# YTM32B1HA0 register map
Vendor: YTMicro; File version: 1.0
CPU: little endian, MPU, FPU, 2 interrupt priority bits
Registers are 32-bit, read-write, reset 0x0 unless marked. A register's access mark holds for its fields unless they carry their own. Offsets are from the block's base; [hi:lo] are bit positions; {n}, {i} and the like mark numbered series; 'fields as' and 'values as' point back to an identical list.

## ENET (part 4 of 10) — Ethernet Quality-of-Service
Base 0x401E4000; register names take the prefix ENET_
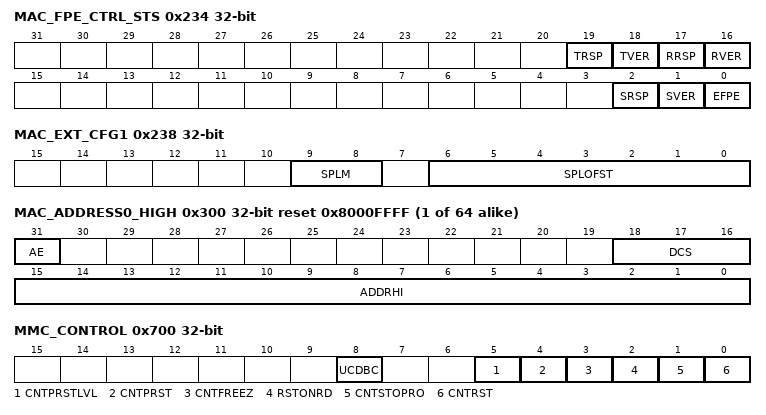
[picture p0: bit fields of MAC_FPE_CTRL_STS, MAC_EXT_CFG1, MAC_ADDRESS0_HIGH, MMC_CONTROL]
0x234 MAC_FPE_CTRL_STS — This register controls the operation of Frame Preemption.
  [19] TRSP — Set when a Respond mPacket is transmitted (triggered by setting SRSP field). An interrupt can be generated for this event if FPEIE bit of MAC_Interrupt_Enable is set. Access restriction applies. Clears on read (or write of 1 when RCWE bit in MAC_CSR_SW_Ctrl register is set). Self-set to 1 on internal event.
    0=Not transmitted Respond Frame; 1=Transmitted Respond Frame
  [18] TVER — Set when a Verify mPacket is transmitted (triggered by setting SVER field). An interrupt can be generated for this event if FPEIE bit of MAC_Interrupt_Enable is set. Access restriction applies. Clears on read (or write of 1 when RCWE bit in MAC_CSR_SW_Ctrl register is set). Self-set to 1 on internal event.
    0=Not transmitted Verify Frame; 1=Transmitted Verify Frame
  [17] RRSP — Set when a Respond mPacket is received (triggered by setting SRSP field). An interrupt can be generated for this event if FPEIE bit of MAC_Interrupt_Enable is set. Access restriction applies. Clears on read (or write of 1 when RCWE bit in MAC_CSR_SW_Ctrl register is set). Self-set to 1 on internal event.
    0=Not received Respond Frame; 1=Received Respond Frame
  [16] RVER — Set when a Verify mPacket is received (triggered by setting SVER field). An interrupt can be generated for this event if FPEIE bit of MAC_Interrupt_Enable is set. Access restriction applies. Clears on read (or write of 1 when RCWE bit in MAC_CSR_SW_Ctrl register is set). Self-set to 1 on internal event.
    0=Not received Verify Frame; 1=Received Verify Frame
  [2] SRSP — When set indicates hardware to send a Respond mPacket. Reset by hardware after sending the Respond mPacket. Access restriction applies. Setting 1 sets. Self-cleared. Setting 0 has no effect.
    0=Send Respond mPacket is disabled; 1=Send Respond mPacket is enabled
  [1] SVER — When set indicates hardware to send a Verify mPacket. Reset by hardware after sending the Verify mPacket. Access restriction applies. Setting 1 sets. Self-cleared. Setting 0 has no effect.
    0=Send Verify mPacket is disabled; 1=Send Verify mPacket is enabled
  [0] EFPE — When set Frame Preemption Tx functionality is enabled.
    0=Tx Frame Preemption is disabled; 1=Tx Frame Preemption is enabled
0x238 MAC_EXT_CFG1 — This register contains Split mode control field and offset field for Split Header feature.
  [9:8] SPLM — These bits indicate the mode of splitting the incoming Rx packets. They are
    0=Split at L3/L4 header; 1=Split at L2 header with an offset. Always Split at SPLOFST bytes from the beginning of Length/Type field of the Frame; 2=Combination mode: Split similar to SPLM=00 for IP packets that are untagged or tagged and VLAN stripped
  [6:0] SPLOFST — These bits indicate the value of offset from the beginning of Length/Type field at which header split should take place when the appropriate SPLM is selected. The reset value of this field is 2 bytes indicating a split at L2 header. Value is in terms of bytes.
0x240 MAC_PRESN_TIME_NS — This register contains the 32-bit binary rollover equivalent time of the PTP System Time in ns
  [31:0] MPTN — These bits indicate the value of the 32-bit binary rollover equivalent time of the PTP System Time in ns
0x244 MAC_PRESN_TIME_UPDT — This field holds the 32-bit value of MAC 1722 Presentation Time in ns, that should be added to the Current Presentation Time Counter value. Init happens when TSINIT is set, and update happens when the TSUPDT bit is set (TSINIT and TSINIT defined in MAC_Timestamp_ Control register).
  [31:0] MPTU — This field holds the init value or the update value for the presentation time. When used for update, this field holds the 32-bit value in ns, that should be added to the Current Presentation Time Counter value. Init happens when TSINIT is set, and update happens when the TSUPDT bit is set (TSINIT and TSINIT defined in MAC_Timestamp_ Control register). When ADDSUB field of MAC_System_Time_Nanoseconds_Update is set, this value is directly used for subtraction
{0x300+8i} MAC_ADDRESS{i}_HIGH reset 0x8000FFFF (i=0..63) — The MAC Address0 High register holds the upper 16 bits of the first 6-byte MAC address of the station. The first DA byte that is received on the (G)MII interface corresponds to the LS byte (Bits [7:0]) of the MAC Address Low register. For example, if 0x112233445566 is received (0x11 in lane 0 of the first column) on the (G)MII as the destination address, then the MacAddress0 Register [47:0] is compared with 0x665544332211. If the MAC address registers are configured to be double-synchronized to the (G)MII clock domains, then the synchronization is triggered only when Bits[31:24] (in little-endian mode) or Bits[7:0] (in big-endian mode) of the MAC Address0 Low Register are written. For proper synchronization updates, the consecutive writes to this Address Low Register should be performed after at least four clock cycles in the destination clock domain.
  [31] AE ro — This bit is always set to 1.
    0=INVALID : This bit must be always set to 1; 1=This bit is always set to 1
  [18:16] DCS — If the PDC bit of MAC_Ext_Configuration register is not set: This field contains the binary representation of the DMA Channel number to which an Rx packet whose DA matches the MAC Address0 content is routed. If the PDC bit of MAC_Ext_Configuration register is set: This field contains the one-hot representation of one or more DMA Channel numbers to which an Rx packet whose DA matches the MAC Address0 content is routed.
  [15:0] ADDRHI — This field contains the upper 16 bits [47:32] of the first 6-byte MAC address. The MAC uses this field for filtering the received packets and inserting the MAC address in the Transmit Flow Control (Pause) Packets.
{0x304+8i} MAC_ADDRESS{i}_LOW reset 0xFFFFFFFF (i=0..63)
  [31:0] ADDRLO — This field contains the lower 32 bits [31:0] of the first 6-byte MAC address. The MAC uses this field for filtering the received packets and inserting the MAC address in the Transmit Flow Control (Pause) Packets.
0x700 MMC_CONTROL — This register establishes the operating mode of MMC.
  [8] UCDBC — Note: The CNTRST bit has a higher priority than the CNTPRST bit. Therefore, when the software tries to set both bits in the same write cycle, all counters are cleared and the CNTPRST bit is not set. When set, the MAC updates all related MMC Counters for Broadcast packets that are dropped because of the setting of the DBF bit of MAC_Packet_Filter register. When reset, the MMC Counters are not updated for dropped Broadcast packets.
    0=Update MMC Counters for Dropped Broadcast Packets is disabled; 1=Update MMC Counters for Dropped Broadcast Packets is enabled
  [5] CNTPRSTLVL — When this bit is low and the CNTPRST bit is set, all MMC counters get preset to almost-half value. All octet counters get preset to 0x7FFF_F800 (Half 2KBytes) and all packet-counters gets preset to 0x7FFF_FFF0 (Half 16). When this bit is high and the CNTPRST bit is set, all MMC counters get preset to almost-full value. All octet counters get preset to 0xFFFF_F800 (Full 2KBytes) and all packet-counters gets preset to 0xFFFF_FFF0 (Full 16). For 16-bit counters, the almost-half preset values are 0x7800 and 0x7FF0 for the respective octet and packet counters. Similarly, the almost-full preset values for the 16-bit counters are 0xF800 and 0xFFF0.
    0=Full-Half Preset is disabled; 1=Full-Half Preset is enabled
  [4] CNTPRST — When this bit is set, all counters are initialized or preset to almost full or almost half according to the CNTPRSTLVL bit. This bit is cleared automatically after 1 clock cycle. This bit, along with the CNTPRSTLVL bit, is useful for debugging and testing the assertion of interrupts because of MMC counter becoming half-full or full. Access restriction applies. Self-cleared. Setting 0 clears. Setting 1 sets.
    0=Counters Preset is disabled; 1=Counters Preset is enabled
  [3] CNTFREEZ — When this bit is set, it freezes all MMC counters to their current value. Until this bit is reset to 0, no MMC counter is updated because of any transmitted or received packet. If any MMC counter is read with the Reset on Read bit set, then that counter is also cleared in this mode.
    0=MMC Counter Freeze is disabled; 1=MMC Counter Freeze is enabled
  [2] RSTONRD — When this bit is set, the MMC counters are reset to zero after Read (self-clearing after reset). The counters are cleared when the least significant byte lane (Bits[7:0]) is read.
    0=Reset on Read is disabled; 1=Reset on Read is enabled
  [1] CNTSTOPRO — When this bit is set, the counter does not roll over to zero after reaching the maximum value.
    0=Counter Stop Rollover is disabled; 1=Counter Stop Rollover is enabled
  [0] CNTRST — When this bit is set, all counters are reset. This bit is cleared automatically after 1 clock cycle. Access restriction applies. Self-cleared. Setting 0 clears. Setting 1 sets.
    0=Counters are not reset; 1=All counters are reset
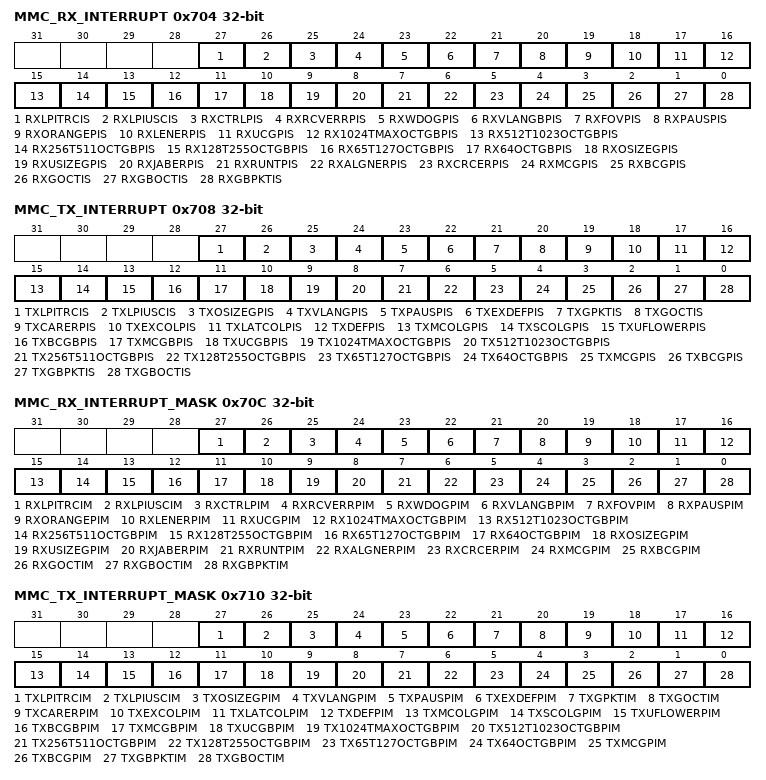
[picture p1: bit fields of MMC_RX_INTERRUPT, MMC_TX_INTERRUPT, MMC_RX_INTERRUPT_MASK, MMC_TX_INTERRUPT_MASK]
0x704 MMC_RX_INTERRUPT ro — This register maintains the interrupts generated from all Receive statistics counters. The MMC Receive Interrupt register maintains the interrupts that are generated when the following occur: - Receive statistic counters reach half of their maximum values (0x8000_0000 for 32 bit counter and 0x8000 for 16 bit counter). - Receive statistic counters cross their maximum values (0xFFFF_FFFF for 32 bit counter and 0xFFFF for 16 bit counter). When the Counter Stop Rollover is set, interrupts are set but the counter remains at all-ones. The MMC Receive Interrupt register is a 32 bit register. An interrupt bit is cleared when the respective MMC counter that caused the interrupt is read. The least significant byte lane (Bits[7:0]) of the respective counter must be read to clear the interrupt bit. Note: R_SS_RC means that this register bit is set internally, and it is cleared when the Counter register is read.
  [27] RXLPITRCIS rw — This bit is set when the Rx_LPI_Tran_Cntr counter reaches half of the maximum value or the maximum value. Access restriction applies. Clears on read. Self-set to 1 on internal event.
    0=MMC Receive LPI transition Counter Interrupt Status not detected; 1=MMC Receive LPI transition Counter Inter- rupt Status detected
  [26] RXLPIUSCIS rw — This bit is set when the Rx_LPI_USEC_Cntr counter reaches half of the maximum value or the maximum value. Access restriction applies. Clears on read. Self-set to 1 on internal event.
    0=MMC Receive LPI microsecond Counter Interrupt Status not detected; 1=MMC Receive LPI microsecond Counter Interrupt Status detected
  [25] RXCTRLPIS rw — This bit is set when the rxctrlpackets_g counter reaches half of the maximum value or the maximum value. Access restriction applies. Clears on read. Self-set to 1 on internal event.
    0=MMC Receive Control Packet Counter Interrupt Status not detected; 1=MMC Receive Control Packet Counter Interrupt Status detected
  [24] RXRCVERRPIS rw — This bit is set when the rxrcverror counter reaches half of the maximum value or the maximum value. Access restriction applies. Clears on read. Self-set to 1 on internal event.
    0=MMC Receive Error Packet Counter Interrupt Status not detected; 1=MMC Receive Error Packet Counter Inter- rupt Status detected
  [23] RXWDOGPIS rw — This bit is set when the rxwatchdog error counter reaches half of the maximum value or the maximum value. Access restriction applies. Clears on read. Self-set to 1 on internal event.
    0=MMC Receive Watchdog Error Packet Counter Interrupt Status not detected; 1=MMC Receive Watchdog Error Packet Counter Interrupt Status detected
  [22] RXVLANGBPIS rw — This bit is set when the rxvlanpackets_gb counter reaches half of the maximum value or the maximum value. Access restriction applies. Clears on read. Self-set to 1 on internal event.
    0=MMC Receive VLAN Good Bad Packet Counter Interrupt Status not detected; 1=MMC Receive VLAN Good Bad Packet Counter Interrupt Status detected
  [21] RXFOVPIS rw — This bit is set when the rxfifoflow counter reaches half of the maximum value or the maximum value. Access restriction applies. Clears on read. Self-set to 1 on internal event.
    0=MMC Receive FIFO Overflow Packet Counter Interrupt Status not detected; 1=MMC Receive FIFO Overflow Packet Counter Interrupt Status detected
  [20] RXPAUSPIS rw — This bit is set when the rxpausepackets counter reaches half of the maximum value or the maximum value. Access restriction applies. Clears on read. Self-set to 1 on internal event.
    0=MMC Receive Pause Packet Counter Interrupt Status not detected; 1=MMC Receive Pause Packet Counter Interrupt Status detected
  [19] RXORANGEPIS rw — This bit is set when the rxoutofrangetype counter reaches half of the maximum value or the maximum value. Access restriction applies. Clears on read. Self-set to 1 on internal event.
    0=MMC Receive Out Of Range Error Packet Counter Interrupt Status not detected; 1=MMC Receive Out Of Range Error Packet Counter Interrupt Status detected
  [18] RXLENERPIS rw — This bit is set when the rxlengtherror counter reaches half of the maximum value or the maximum value. Access restriction applies. Clears on read. Self-set to 1 on internal event.
    0=MMC Receive Length Error Packet Counter Interrupt Status not detected; 1=MMC Receive Length Error Packet Counter Interrupt Status detected
  [17] RXUCGPIS rw — This bit is set when the rxunicastpackets_g counter reaches half of the maximum value or the maximum value. Access restriction applies. Clears on read. Self-set to 1 on internal event.
    0=MMC Receive Unicast Good Packet Counter Interrupt Status not detected; 1=MMC Receive Unicast Good Packet Counter Interrupt Status detected
  [16] RX1024TMAXOCTGBPIS rw — This bit is set when the rx1024tomaxoctets_gb counter reaches half of the maximum value or the maximum value. Access restriction applies. Clears on read. Self-set to 1 on internal event.
    0=MMC Receive 1024 to Maximum Octets Good Bad Packet Counter Interrupt Status not detected; 1=MMC Receive 1024 to Maximum Octets Good Bad Packet Counter Interrupt Status detected
  [15] RX512T1023OCTGBPIS rw — This bit is set when the rx512to1023octets_gb counter reaches half of the maximum value or the maximum value. Access restriction applies. Clears on read. Self-set to 1 on internal event.
    0=MMC Receive 512 to 1023 Octets Good Bad Packet Counter Interrupt Status not detected; 1=MMC Receive 512 to 1023 Octets Good Bad Packet Counter Interrupt Status detected
  [14] RX256T511OCTGBPIS rw — This bit is set when the rx256to511octets_gb counter reaches half of the maximum value or the maximum value. Access restriction applies. Clears on read. Self-set to 1 on internal event.
    0=MMC Receive 256 to 511 Octets Good Bad Packet Counter Interrupt Status not detected; 1=MMC Receive 256 to 511 Octets Good Bad Packet Counter Interrupt Status detected
  [13] RX128T255OCTGBPIS rw — This bit is set when the rx128to255octets_gb counter reaches half of the maximum value or the maximum value. Access restriction applies. Clears on read. Self-set to 1 on internal event.
    0=MMC Receive 128 to 255 Octets Good Bad Packet Counter Interrupt Status not detected; 1=MMC Receive 128 to 255 Octets Good Bad Packet Counter Interrupt Status detected
  [12] RX65T127OCTGBPIS rw — This bit is set when the rx65to127octets_gb counter reaches half of the maximum value or the maximum value. Access restriction applies. Clears on read. Self-set to 1 on internal event.
    0=MMC Receive 65 to 127 Octets Good Bad Packet Counter Interrupt Status not detected; 1=MMC Receive 65 to 127 Octets Good Bad Packet Counter Interrupt Status detected
  [11] RX64OCTGBPIS rw — This bit is set when the rx64octets_gb counter reaches half of the maximum value or the maximum value. Access restriction applies. Clears on read. Self-set to 1 on internal event.
    0=MMC Receive 64 Octets Good Bad Packet Counter Interrupt Status not detected; 1=MMC Receive 64 Octets Good Bad Packet Counter Interrupt Status detected
  [10] RXOSIZEGPIS rw — This bit is set when the rxoversize_g counter reaches half of the maximum value or the maximum value. Access restriction applies. Clears on read. Self-set to 1 on internal event.
    0=MMC Receive Oversize Good Packet Counter Interrupt Status not detected; 1=MMC Receive Oversize Good Packet Counter Interrupt Status detected
  [9] RXUSIZEGPIS rw — This bit is set when the rxundersize_g counter reaches half of the maximum value or the maximum value. Access restriction applies. Clears on read. Self-set to 1 on internal event.
    0=MMC Receive Undersize Good Packet Counter Interrupt Status not detected; 1=MMC Receive Undersize Good Packet Counter Interrupt Status detected
  [8] RXJABERPIS rw — This bit is set when the rxjabber counter reaches half of the maximum value or the maximum value. Access restriction applies. Clears on read. Self-set to 1 on internal event.
    0=MMC Receive Jabber Error Packet Counter Interrupt Status not detected; 1=MMC Receive Jabber Error Packet Counter Interrupt Status detected
  [7] RXRUNTPIS rw — This bit is set when the rxrunt counter reaches half of the maximum value or the maximum value. Access restriction applies. Clears on read. Self-set to 1 on internal event.
    0=MMC Receive Runt Packet Counter Interrupt Status not detected; 1=MMC Receive Runt Packet Counter Interrupt Status detected
  [6] RXALGNERPIS rw — This bit is set when the rxalignmenterror counter reaches half of the maximum value or the maximum value. Access restriction applies. Clears on read. Self-set to 1 on internal event.
    0=MMC Receive Alignment Error Packet Counter Interrupt Status not detected; 1=MMC Receive Alignment Error Packet Counter Interrupt Status detected
  [5] RXCRCERPIS rw — This bit is set when the rxcrcerror counter reaches half of the maximum value or the maximum value. Access restriction applies. Clears on read. Self-set to 1 on internal event.
    0=MMC Receive CRC Error Packet Counter Interrupt Status not detected; 1=MMC Receive CRC Error Packet Counter Interrupt Status detected
  [4] RXMCGPIS rw — This bit is set when the rxmulticast_g counter reaches half of the maximum value or the maximum value. Access restriction applies. Clears on read. Self-set to 1 on internal event.
    0=MMC Receive Multicast Good Packet Counter Interrupt Status not detected; 1=MMC Receive Multicast Good Packet Counter Interrupt Status detected
  [3] RXBCGPIS rw — This bit is set when the rxbroadcast_g counter reaches half of the maximum value or the maximum value. Access restriction applies. Clears on read. Self-set to 1 on internal event.
    0=MMC Receive Broadcast Good Packet Counter Interrupt Status not detected; 1=MMC Receive Broadcast Good Packet Counter Interrupt Status detected
  [2] RXGOCTIS rw — This bit is set when the rxgoodoctets counter reaches half of the maximum value or the maximum value. Access restriction applies. Clears on read. Self-set to 1 on internal event.
    0=MMC Receive Good Octets Counter Interrupt Status not detected; 1=MMC Receive Good Octets Counter Interrupt Status detected
  [1] RXGBOCTIS rw — This bit is set when the rxgoodandbadoctets counter reaches half of the maximum value or the maximum value. Access restriction applies. Clears on read. Self-set to 1 on internal event.
    0=MMC Receive Good and Bad Octets Counter Interrupt Status not detected; 1=MMC Receive Good and Bad Octets Counter Interrupt Status detected
  [0] RXGBPKTIS rw — This bit is set when the rxgoodandbadpacket counter reaches half of the maximum value or the maximum value. Access restriction applies. Clears on read. Self-set to 1 on internal event.
    0=MMC Receive Good and Bad Packet Counter Interrupt Status not detected; 1=MMC Receive Good and Bad Packet Counter Interrupt Status detected
0x708 MMC_TX_INTERRUPT ro — This register contains the interrupt status bits for the MMC Transmit counters.
  [27] TXLPITRCIS rw — This bit is set when the Tx_LPI_Tran_Cntr counter reaches half of the maximum value or the maximum value. Access restriction applies. Clears on read. Self-set to 1 on internal event.
    0=MMC Transmit LPI transition counter interrupt status not detected; 1=MMC Transmit LPI transition counter interrupt status detected
  [26] TXLPIUSCIS rw — This bit is set when the Tx_LPI_USEC_Cntr counter reaches half of the maximum value or the maximum value. Access restriction applies. Clears on read. Self-set to 1 on internal event.
    0=MMC Transmit LPI microsecond counter interrupt status not detected; 1=MMC Transmit LPI microsecond counter interrupt status detected
  [25] TXOSIZEGPIS rw — This bit is set when the txoversize_g counter reaches half of the maximum value or the maximum value. Access restriction applies. Clears on read. Self-set to 1 on internal event.
    0=MMC Transmit Oversize Good Packet Counter Interrupt Status not detected; 1=MMC Transmit Oversize Good Packet Counter Interrupt Status detected
  [24] TXVLANGPIS rw — MMC Transmit VLAN Good Packet Counter Interrupt Status This bit is set when the txvlanpackets_g counter reaches half of the maximum value or the maximum value. Access restriction applies. Clears on read. Self-set to 1 on internal event.
    0=MMC Transmit VLAN Good Packet Counter Interrupt Status not detected; 1=MMC Transmit VLAN Good Packet Counter Interrupt Status detected
  [23] TXPAUSPIS rw — This bit is set when the txpausepacketserror counter reaches half of the maximum value or the maximum value. Access restriction applies. Clears on read. Self-set to 1 on internal event.
    0=MMC Transmit Pause Packet Counter Interrupt Status not detected; 1=MMC Transmit Pause Packet Counter Interrupt Status detected
  [22] TXEXDEFPIS rw — This bit is set when the txexcessdef counter reaches half of the maximum value or the maximum value. Access restriction applies. Clears on read. Self-set to 1 on internal event.
    0=MMC Transmit Excessive Deferral Packet Counter Interrupt Status not detected; 1=MMC Transmit Excessive Deferral Packet Counter Interrupt Status detected
  [21] TXGPKTIS rw — This bit is set when the txpacketcount_g counter reaches half of the maximum value or the maximum value. Access restriction applies. Clears on read. Self-set to 1 on internal event.
    0=MMC Transmit Good Packet Counter Interrupt Status not detected; 1=MMC Transmit Good Packet Counter Interrupt Status detected
  [20] TXGOCTIS rw — This bit is set when the txoctetcount_g counter reaches half of the maximum value or the maximum value. Access restriction applies. Clears on read. Self-set to 1 on internal event.
    0=MMC Transmit Good Octets Counter Interrupt Status not detected; 1=MMC Transmit Good Octets Counter Interrupt Status detected
  [19] TXCARERPIS rw — This bit is set when the txcarriererror counter reaches half of the maximum value or the maximum value. Access restriction applies. Clears on read. Self-set to 1 on internal event.
    0=MMC Transmit Carrier Error Packet Counter Interrupt Status not detected; 1=MMC Transmit Carrier Error Packet Counter Interrupt Status detected
  [18] TXEXCOLPIS rw — This bit is set when the txexesscol counter reaches half of the maximum value or the maximum value. Access restriction applies. Clears on read. Self-set to 1 on internal event.
    0=MMC Transmit Excessive Collision Packet Counter Interrupt Status not detected; 1=MMC Transmit Excessive Collision Packet Counter Interrupt Status detected
  [17] TXLATCOLPIS rw — This bit is set when the txlatecol counter reaches half of the maximum value or the maximum value. Access restriction applies. Clears on read. Self-set to 1 on internal event.
    0=MMC Transmit Late Collision Packet Counter Interrupt Status not detected; 1=MMC Transmit Late Collision Packet Counter Interrupt Status detected
  [16] TXDEFPIS rw — This bit is set when the txdeferred counter reaches half of the maximum value or the maximum value. Access restriction applies. Clears on read. Self-set to 1 on internal event.
    0=MMC Transmit Deferred Packet Counter Interrupt Status not detected; 1=MMC Transmit Deferred Packet Counter Interrupt Status detected
  [15] TXMCOLGPIS rw — This bit is set when the txmulticol_g counter reaches half of the maximum value or the maximum value. Access restriction applies. Clears on read. Self-set to 1 on internal event.
    0=MMC Transmit Multiple Collision Good Packet Counter Interrupt Status not detected; 1=MMC Transmit Multiple Collision Good Packet Counter Interrupt Status detected
  [14] TXSCOLGPIS rw — This bit is set when the txsinglecol_g counter reaches half of the maximum value or the maximum value. Access restriction applies. Clears on read. Self-set to 1 on internal event.
    0=MMC Transmit Single Collision Good Packet Counter Interrupt Status not detected; 1=MMC Transmit Single Collision Good Packet Counter Interrupt Status detected
  [13] TXUFLOWERPIS rw — This bit is set when the txunderflowerror counter reaches half of the maximum value or the maximum value. Access restriction applies. Clears on read. Self-set to 1 on internal event.
    0=MMC Transmit Underflow Error Packet Counter Interrupt Status not detected; 1=MMC Transmit Underflow Error Packet Counter Interrupt Status detected
  [12] TXBCGBPIS rw — This bit is set when the txbroadcastpackets_gb counter reaches half of the maximum value or the maximum value. Access restriction applies. Clears on read. Self-set to 1 on internal event.
    0=MMC Transmit Broadcast Good Packet Counter Interrupt Status not detected; 1=MMC Transmit Broadcast Good Packet Counter Interrupt Status detected
  [11] TXMCGBPIS rw — This bit is set when the txmulticastpackets_gb counter reaches half of the maximum value or the maximum value. Access restriction applies. Clears on read. Self-set to 1 on internal event.
    0=MMC Transmit Multicast Good Packet Counter Interrupt Status not detected; 1=MMC Transmit Multicast Good Packet Counter Interrupt Status detected
  [10] TXUCGBPIS rw — This bit is set when the txunicastpackets_gb counter reaches half of the maximum value or the maximum value. Access restriction applies. Clears on read. Self-set to 1 on internal event.
    0=MMC Transmit Unicast Good Bad Packet Counter Interrupt Status not detected; 1=MMC Transmit Unicast Good Bad Packet Counter Interrupt Status detected
  [9] TX1024TMAXOCTGBPIS rw — This bit is set when the tx1024tomaxoctets_gb counter reaches half of the maximum value or the maximum value. Access restriction applies. Clears on read. Self-set to 1 on internal event.
    0=MMC Transmit 1024 to Maximum Octet Good Bad Packet Counter Interrupt Status not detected; 1=MMC Transmit 1024 to Maximum Octet Good Bad Packet Counter Interrupt Status detected
  [8] TX512T1023OCTGBPIS rw — This bit is set when the tx512to1023octets_gb counter reaches half of the maximum value or the maximum value. Access restriction applies. Clears on read. Self-set to 1 on internal event.
    0=MMC Transmit 512 to 1023 Octet Good Bad Packet Counter Interrupt Status not detected; 1=MMC Transmit 512 to 1023 Octet Good Bad Packet Counter Interrupt Status detected
  [7] TX256T511OCTGBPIS rw — This bit is set when the tx256to511octets_gb counter reaches half of the maximum value or the maximum value. Access restriction applies. Clears on read. Self-set to 1 on internal event.
    0=MMC Transmit 256 to 511 Octet Good Bad Packet Counter Interrupt Status not detected; 1=MMC Transmit 256 to 511 Octet Good Bad Packet Counter Interrupt Status detected
  [6] TX128T255OCTGBPIS rw — This bit is set when the tx128to255octets_gb counter reaches half of the maximum value or the maximum value. Access restriction applies. Clears on read. Self-set to 1 on internal event.
    0=MMC Transmit 128 to 255 Octet Good Bad Packet Counter Interrupt Status not detected; 1=MMC Transmit 128 to 255 Octet Good Bad Packet Counter Interrupt Status detected
  [5] TX65T127OCTGBPIS rw — This bit is set when the tx65to127octets_gb counter reaches half of the maximum value or the maximum value. Access restriction applies. Clears on read. Self-set to 1 on internal event.
    0=MMC Transmit 65 to 127 Octet Good Bad Packet Counter Interrupt Status not detected; 1=MMC Transmit 65 to 127 Octet Good Bad Packet Counter Interrupt Status detected
  [4] TX64OCTGBPIS rw — This bit is set when the tx64octets_gb counter reaches half of the maximum value or the maximum value. Access restriction applies. Clears on read. Self-set to 1 on internal event.
    0=MMC Transmit 64 Octet Good Bad Packet Counter Interrupt Status not detected; 1=MMC Transmit 64 Octet Good Bad Packet Counter Interrupt Status detected
  [3] TXMCGPIS rw — This bit is set when the txbroadcastpackets_g counter reaches half of the maximum value or the maximum value. Access restriction applies. Clears on read. Self-set to 1 on internal event.
    values as TXMCGBPIS
  [2] TXBCGPIS rw — This bit is set when the txmulticastpackets_g counter reaches half of the maximum value or the maximum value. Access restriction applies. Clears on read. Self-set to 1 on internal event.
    values as TXBCGBPIS
  [1] TXGBPKTIS rw — This bit is set when the txgoodbadpackets counter reaches half of the maximum value or the maximum value. Access restriction applies. Clears on read. Self-set to 1 on internal event.
    0=MMC Transmit Good Bad Packet Counter Interrupt Status not detected; 1=MMC Transmit Good Bad Packet Counter Interrupt Status detected
  [0] TXGBOCTIS rw — This bit is set when the txoctetcount_gb counter reaches half of the maximum value or the maximum value. Access restriction applies. Clears on read. Self-set to 1 on internal event.
    0=MMC Transmit Good Bad Octet Counter Interrupt Status not detected; 1=MMC Transmit Good Bad Octet Counter Interrupt Status detected
0x70C MMC_RX_INTERRUPT_MASK ro — This register maintains the masks for interrupts generated from all Receive statistics counters. The MMC Receive Interrupt Mask register maintains the masks for the interrupts generated when receive statistic counters reach half of their maximum value or the maximum values.
  [27] RXLPITRCIM rw — Setting this bit masks the interrupt when the Rx_LPI_Tran_Cntr counter reaches half of the maximum value or the maximum value.
    0=MMC Receive LPI transition counter inter- rupt Mask is disabled; 1=MMC Receive LPI transition counter inter- rupt Mask is enabled
  [26] RXLPIUSCIM rw — Setting this bit masks the interrupt when the Rx_LPI_USEC_Cntr counter reaches half of the maximum value or the maximum value.
    0=MMC Receive LPI microsecond counter interrupt Mask is disabled; 1=MMC Receive LPI microsecond counter interrupt Mask is enabled
  [25] RXCTRLPIM rw — Setting this bit masks the interrupt when the rxctrlpackets_g counter reaches half of the maximum value or the maximum value.
    0=MMC Receive Control Packet Counter Interrupt Mask is disabled; 1=MMC Receive Control Packet Counter Interrupt Mask is enabled
  [24] RXRCVERRPIM rw — Setting this bit masks the interrupt when the rxrcverror counter reaches half of the maximum value or the maximum value.
    0=MMC Receive Error Packet Counter Interrupt Mask is disabled; 1=MMC Receive Error Packet Counter Interrupt Mask is enabled
  [23] RXWDOGPIM rw — Setting this bit masks the interrupt when the rxwatchdogerror counter reaches half of the maximum value or the maximum value.
    0=MMC Receive Watchdog Error Packet Counter Interrupt Mask is disabled; 1=MMC Receive Watchdog Error Packet Counter Interrupt Mask is enabled
  [22] RXVLANGBPIM rw — Setting this bit masks the interrupt when the rxvlanpackets_gb counter reaches half of the maximum value or the maximum value.
    0=MMC Receive VLAN Good Bad Packet Counter Interrupt Mask is disabled; 1=MMC Receive VLAN Good Bad Packet Counter Interrupt Mask is enabled
  [21] RXFOVPIM rw — Setting this bit masks the interrupt when the rxfifooverflow counter reaches half of the maximum value or the maximum value.
    0=MMC Receive FIFO Overflow Packet Counter Interrupt Mask is disabled; 1=MMC Receive FIFO Overflow Packet Counter Interrupt Mask is enabled
  [20] RXPAUSPIM rw — Setting this bit masks the interrupt when the rxpausepackets counter reaches half of the maximum value or the maximum value.
    0=MMC Receive Pause Packet Counter Interrupt Mask is disabled; 1=MMC Receive Pause Packet Counter Interrupt Mask is enabled
  [19] RXORANGEPIM rw — Setting this bit masks the interrupt when the rxoutofrangetype counter reaches half of the maximum value or the maximum value.
    0=MMC Receive Out Of Range Error Packet Counter Interrupt Mask is disabled; 1=MMC Receive Out Of Range Error Packet Counter Interrupt Mask is enabled
  [18] RXLENERPIM rw — MMC Receive Length Error Packet Counter Interrupt Mask Setting this bit masks the interrupt when the rxlengtherror counter reaches half of the maximum value or the maximum value.
    0=MMC Receive Length Error Packet Counter Interrupt Mask is disabled; 1=MMC Receive Length Error Packet Counter Interrupt Mask is enabled
  [17] RXUCGPIM rw — Setting this bit masks the interrupt when the rxunicastpackets_g counter reaches half of the maximum value or the maximum value.
    0=MMC Receive Unicast Good Packet Counter Interrupt Mask is disabled; 1=MMC Receive Unicast Good Packet Counter Interrupt Mask is enabled
  [16] RX1024TMAXOCTGBPIM rw — Setting this bit masks the interrupt when the rx1024tomaxoctets_gb counter reaches half of the maximum value or the maximum value.
    0=MMC Receive 1024 to Maximum Octet Good Bad Packet Counter Interrupt Mask is disabled; 1=MMC Receive 1024 to Maximum Octet Good Bad Packet Counter Interrupt Mask is enabled
  [15] RX512T1023OCTGBPIM rw — Setting this bit masks the interrupt when the rx512to1023octets_gb counter reaches half of the maximum value or the maximum value.
    0=MMC Receive 512 to 1023 Octet Good Bad Packet Counter Interrupt Mask is disabled; 1=MMC Receive 512 to 1023 Octet Good Bad Packet Counter Interrupt Mask is enabled
  [14] RX256T511OCTGBPIM rw — Setting this bit masks the interrupt when the rx256to511octets_gb counter reaches half of the maximum value or the maximum value.
    0=MMC Receive 256 to 511 Octet Good Bad Packet Counter Interrupt Mask is disabled; 1=MMC Receive 256 to 511 Octet Good Bad Packet Counter Interrupt Mask is enabled
  [13] RX128T255OCTGBPIM rw — Setting this bit masks the interrupt when the rx128to255octets_gb counter reaches half of the maximum value or the maximum value.
    0=MMC Receive 128 to 255 Octet Good Bad Packet Counter Interrupt Mask is disabled; 1=MMC Receive 128 to 255 Octet Good Bad Packet Counter Interrupt Mask is enabled
  [12] RX65T127OCTGBPIM rw — Setting this bit masks the interrupt when the rx65to127octets_gb counter reaches half of the maximum value or the maximum value.
    0=MMC Receive 65 to 127 Octet Good Bad Packet Counter Interrupt Mask is disabled; 1=MMC Receive 65 to 127 Octet Good Bad Packet Counter Interrupt Mask is enabled
  [11] RX64OCTGBPIM rw — Setting this bit masks the interrupt when the rx64octets_gb counter reaches half of the maximum value or the maximum value.
    0=MMC Receive 64 Octet Good Bad Packet Counter Interrupt Mask is disabled; 1=MMC Receive 64 Octet Good Bad Packet Counter Interrupt Mask is enabled
  [10] RXOSIZEGPIM rw — Setting this bit masks the interrupt when the rxoversizepackets_g counter reaches half of the maximum value or the maximum value.
    0=MMC Receive Oversize Good Packet Counter Interrupt Mask is disabled; 1=MMC Receive Oversize Good Packet Counter Interrupt Mask is enabled
  [9] RXUSIZEGPIM rw — Setting this bit masks the interrupt when the rxundersize_g counter reaches half of the maximum value or the maximum value.
    0=MMC Receive Undersize Good Packet Counter Interrupt Mask is disabled; 1=MMC Receive Undersize Good Packet Counter Interrupt Mask is enabled
  [8] RXJABERPIM rw — Setting this bit masks the interrupt when the rxjabbererror counter reaches half of the maximum value or the maximum value.
    0=MMC Receive Jabber Error Packet Counter Interrupt Mask is disabled; 1=MMC Receive Jabber Error Packet Counter Interrupt Mask is enabled
  [7] RXRUNTPIM rw — Setting this bit masks the interrupt when the rxrunterror counter reaches half of the maximum value or the maximum value.
    0=MMC Receive Runts Packet Counter Interrupt Mask is disabled; 1=MMC Receive Runts Packet Counter Interrupt Mask is enabled
  [6] RXALGNERPIM rw — Setting this bit masks the interrupt when the rxalignmenterror counter reaches half of the maximum value or the maximum value.
    0=MMC Receive Alignment Error Packet Counter Interrupt Mask is disabled; 1=MMC Receive Alignment Error Packet Counter Interrupt Mask is enabled
  [5] RXCRCERPIM rw — Setting this bit masks the interrupt when the rxcrcerror counter reaches half of the maximum value or the maximum value.
    0=MMC Receive CRC Error Packet Counter Interrupt Mask is disabled; 1=MMC Receive CRC Error Packet Counter Interrupt Mask is enabled
  [4] RXMCGPIM rw — Setting this bit masks the interrupt when the rxmulticastpackets_g counter reaches half of the maximum value or the maximum value.
    0=MMC Receive Multicast Good Packet Counter Interrupt Mask is disabled; 1=MMC Receive Multicast Good Packet Counter Interrupt Mask is enabled
  [3] RXBCGPIM rw — Setting this bit masks the interrupt when the rxbroadcastpackets_g counter reaches half of the maximum value or the maximum value.
    0=MMC Receive Broadcast Good Packet Counter Interrupt Mask is disabled; 1=MMC Receive Broadcast Good Packet Counter Interrupt Mask is enabled
  [2] RXGOCTIM rw — Setting this bit masks the interrupt when the rxgoodoctets counter reaches half of the maximum value or the maximum value.
    0=MMC Receive Good Octet Counter Interrupt Mask is disabled; 1=MMC Receive Good Octet Counter Interrupt Mask is enabled
  [1] RXGBOCTIM rw — Setting this bit masks the interrupt when the rxoctetcount_gb counter reaches half of the maximum value or the maximum value.
    0=MMC Receive Good and Bad Octet Counter Interrupt Mask is disabled; 1=MMC Receive Good and Bad Octet Counter Interrupt Mask is enabled
  [0] RXGBPKTIM rw — Setting this bit masks the interrupt when the rxpacketcount_gb counter reaches half of the maximum value or the maximum value.
    0=MMC Receive Good and Bad Packet Counter Interrupt Mask is disabled; 1=MMC Receive Good and Bad Packet Counter Interrupt Mask is enabled
0x710 MMC_TX_INTERRUPT_MASK ro — This register maintains the masks for interrupts generated from all Transmit statistics counters. The MMC Transmit Interrupt Mask register maintains the masks for the interrupts generated when the transmit statistic counters reach half of their maximum value or the maximum values. This register is 32 bit wide.
  [27] TXLPITRCIM rw — Setting this bit masks the interrupt when the Tx_LPI_Tran_Cntr counter reaches half of the maximum value or the maximum value.
    0=MMC Transmit LPI transition counter interrupt Mask is disabled; 1=MMC Transmit LPI transition counter interrupt Mask is enabled
  [26] TXLPIUSCIM rw — Setting this bit masks the interrupt when the Tx_LPI_USEC_Cntr counter reaches half of the maximum value or the maximum value.
    0=MMC Transmit LPI microsecond counter interrupt Mask is disabled; 1=MMC Transmit LPI microsecond counter interrupt Mask is enabled
  [25] TXOSIZEGPIM rw — Setting this bit masks the interrupt when the txoversize_g counter reaches half of the maximum value or the maximum value.
    0=MMC Transmit Oversize Good Packet Counter Interrupt Mask is disabled; 1=MMC Transmit Oversize Good Packet Counter Interrupt Mask is enabled
  [24] TXVLANGPIM rw — Setting this bit masks the interrupt when the txvlanpackets_g counter reaches half of the maximum value or the maximum value.
    0=MMC Transmit VLAN Good Packet Counter Interrupt Mask is disabled; 1=MMC Transmit VLAN Good Packet Counter Interrupt Mask is enabled
  [23] TXPAUSPIM rw — Setting this bit masks the interrupt when the txpausepackets counter reaches half of the maximum value or the maximum value.
    0=MMC Transmit Pause Packet Counter Interrupt Mask is disabled; 1=MMC Transmit Pause Packet Counter Interrupt Mask is enabled
  [22] TXEXDEFPIM rw — Setting this bit masks the interrupt when the txexcessive_deferral counter reaches half of the maximum value or the maximum value.
    0=MMC Transmit Excessive Deferral Packet Counter Interrupt Mask is disabled; 1=MMC Transmit Excessive Deferral Packet Counter Interrupt Mask is enabled
  [21] TXGPKTIM rw — Setting this bit masks the interrupt when the txpacketcount_g counter reaches half of the maximum value or the maximum value.
    0=MMC Transmit Good Packet Counter Interrupt Mask is disabled; 1=MMC Transmit Good Packet Counter Interrupt Mask is enabled
  [20] TXGOCTIM rw — Setting this bit masks the interrupt when the txgoodoctets counter reaches half of the maximum value or the maximum value.
    0=MMC Transmit Good Octet Counter Interrupt Mask is disabled; 1=MMC Transmit Good Octet Counter Interrupt Mask is enabled
  [19] TXCARERPIM rw — Setting this bit masks the interrupt when the txcarriererror counter reaches half of the maximum value or the maximum value.
    0=MMC Transmit Carrier Error Packet Counter Interrupt Mask is disabled; 1=MMC Transmit Carrier Error Packet Counter Interrupt Mask is enabled
  [18] TXEXCOLPIM rw — Setting this bit masks the interrupt when the txexcessive_collision counter reaches half of the maximum value or the maximum value.
    0=MMC Transmit Excessive Collision Packet Counter Interrupt Mask is disabled; 1=MMC Transmit Excessive Collision Packet Counter Interrupt Mask is enabled
  [17] TXLATCOLPIM rw — Setting this bit masks the interrupt when the txlate_collision counter reaches half of the maximum value or the maximum value.
    0=MMC Transmit Late Collision Packet Counter Interrupt Mask is disabled; 1=MMC Transmit Late Collision Packet Counter Interrupt Mask is enabled
  [16] TXDEFPIM rw — Setting this bit masks the interrupt when the txdeferred counter reaches half of the maximum value or the maximum value.
    0=MMC Transmit Deferred Packet Counter Interrupt Mask is disabled; 1=MMC Transmit Deferred Packet Counter Interrupt Mask is enabled
  [15] TXMCOLGPIM rw — Setting this bit masks the interrupt when the txmulticollision_g counter reaches half of the maximum value or the maximum value.
    0=MMC Transmit Multiple Collision Good Packet Counter Interrupt Mask is disabled; 1=MMC Transmit Multiple Collision Good Packet Counter Interrupt Mask is enabled
  [14] TXSCOLGPIM rw — Setting this bit masks the interrupt when the txsinglecollision_g counter reaches half of the maximum value or the maximum value.
    0=MMC Transmit Single Collision Good Packet Counter Interrupt Mask is disabled; 1=MMC Transmit Single Collision Good Packet Counter Interrupt Mask is enabled
  [13] TXUFLOWERPIM rw — Setting this bit masks the interrupt when the txunderflowerror counter reaches half of the maximum value or the maximum value.
    0=MMC Transmit Underflow Error Packet Counter Interrupt Mask is disabled; 1=MMC Transmit Underflow Error Packet Counter Interrupt Mask is enabled
  [12] TXBCGBPIM rw — Setting this bit masks the interrupt when the txbroadcastpackets_g counter reaches half of the maximum value or the maximum value.
    0=MMC Transmit Broadcast Good Packet Counter Interrupt Mask is disabled; 1=MMC Transmit Broadcast Good Packet Counter Interrupt Mask is enabled
  [11] TXMCGBPIM rw — Setting this bit masks the interrupt when the txmulticastpackets_g counter reaches half of the maximum value or the maximum value.
    0=MMC Transmit Multicast Good Packet Counter Interrupt Mask is disabled; 1=MMC Transmit Multicast Good Packet Counter Interrupt Mask is enabled
  [10] TXUCGBPIM rw — Setting this bit masks the interrupt when the txunicastpackets_g counter reaches half of the maximum value or the maximum value.
    0=MMC Transmit Unicast Good Packet Counter Interrupt Mask is disabled; 1=MMC Transmit Unicast Good Packet Counter Interrupt Mask is enabled
  [9] TX1024TMAXOCTGBPIM rw — Setting this bit masks the interrupt when the tx1024tomaxoctets_gb counter reaches half of the maximum value or the maximum value.
    0=MMC Transmit 1024 to Maximum Octet Good Packet Counter Interrupt Mask is disabled; 1=MMC Transmit 1024 to Maximum Octet Good Packet Counter Interrupt Mask is enabled
  [8] TX512T1023OCTGBPIM rw — Setting this bit masks the interrupt when the tx512to1023octets_gb counter reaches half of the maximum value or the maximum value.
    0=MMC Transmit 512 to 1023 Octet Good Packet Counter Interrupt Mask is disabled; 1=MMC Transmit 512 to 1023 Octet Good Packet Counter Interrupt Mask is enabled
  [7] TX256T511OCTGBPIM rw — Setting this bit masks the interrupt when the tx256to511octets_gb counter reaches half of the maximum value or the maximum value.
    0=MMC Transmit 256 to 511 Octet Good Packet Counter Interrupt Mask is disabled; 1=MMC Transmit 256 to 511 Octet Good Packet Counter Interrupt Mask is enabled
  [6] TX128T255OCTGBPIM rw — Setting this bit masks the interrupt when the tx128to255octets_gb counter reaches half of the maximum value or the maximum value.
    0=MMC Transmit 128 to 255 Octet Good Packet Counter Interrupt Mask is disabled; 1=MMC Transmit 128 to 255 Octet Good Packet Counter Interrupt Mask is enabled
  [5] TX65T127OCTGBPIM rw — Setting this bit masks the interrupt when the tx65to127octets_gb counter reaches half of the maximum value or the maximum value.
    0=MMC Transmit 65 to 127 Octet Good Packet Counter Interrupt Mask is disabled; 1=MMC Transmit 65 to 127 Octet Good Packet Counter Interrupt Mask is enabled
  [4] TX64OCTGBPIM rw — Setting this bit masks the interrupt when the tx64octets_gb counter reaches half of the maximum value or the maximum value.
    0=MMC Transmit 64 Octet Good Packet Counter Interrupt Mask is disabled; 1=MMC Transmit 64 Octet Good Packet Counter Interrupt Mask is enabled
  [3] TXMCGPIM rw — Setting this bit masks the interrupt when the txmulticastpackets_g counter reaches half of the maximum value or the maximum value.
    values as TXMCGBPIM
  [2] TXBCGPIM rw — Setting this bit masks the interrupt when the txbroadcastpackets_g counter reaches half of the maximum value or the maximum value.
    values as TXBCGBPIM
  [1] TXGBPKTIM rw — Setting this bit masks the interrupt when the txgoodpackets counter reaches half of the maximum value or the maximum value.
    values as TXGPKTIM
  [0] TXGBOCTIM rw — Setting this bit masks the interrupt when the txgoodoctets counter reaches half of the maximum value or the maximum value.
    values as TXGOCTIM
